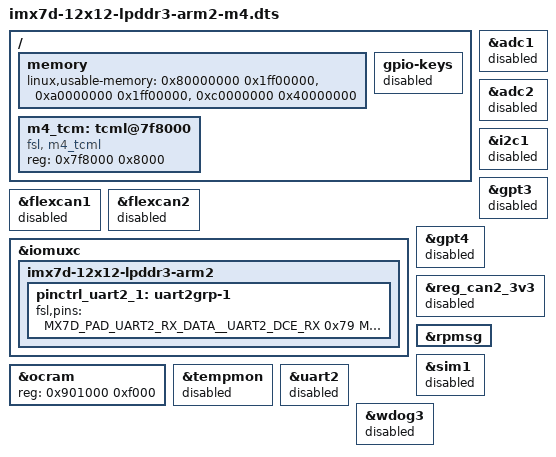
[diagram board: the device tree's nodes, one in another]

#include "imx7d-12x12-lpddr3-arm2.dts"

/ {
	memory {
		linux,usable-memory = <0x80000000 0x1ff00000>,
				<0xa0000000 0x1ff00000>,
				<0xc0000000 0x40000000>;
	};

	gpio-keys {
		status = "disabled";
	};

	m4_tcm: tcml@7f8000 {
		compatible = "fsl, m4_tcml";
		reg = <0x7f8000 0x8000>;
	};
};

&adc1 {
	status = "disabled";
};

&adc2 {
	status = "disabled";
};


&i2c1 {
	status = "disabled";
};

&flexcan1 {
	status = "disabled";
};

&flexcan2 {
	status = "disabled";
};

&iomuxc {
	imx7d-12x12-lpddr3-arm2 {
		pinctrl_uart2_1: uart2grp-1 {
			fsl,pins = <
				MX7D_PAD_UART2_RX_DATA__UART2_DCE_RX	0x79
				MX7D_PAD_UART2_TX_DATA__UART2_DCE_TX	0x79
			>;
		};
	};
};

&gpt3 {
	status = "disabled";
};

&gpt4 {
	status = "disabled";
};

&ocram {
	reg = <0x901000 0xf000>;
};

&reg_can2_3v3 {
	status = "disabled";
};

&rpmsg{
	status = "okay";
};

&sim1 {
	status = "disabled";
};

&tempmon {
	status = "disabled";
};

&uart2 {
	status = "disabled";
};

&wdog3{
	status = "disabled";
};
